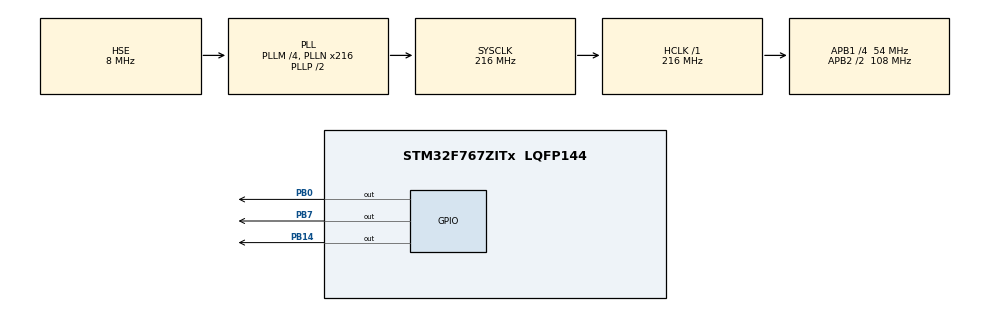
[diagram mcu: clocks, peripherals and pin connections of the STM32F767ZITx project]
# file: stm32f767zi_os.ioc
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Mcu.Family=STM32F7
Mcu.Name=STM32F767ZITx
Mcu.Package=LQFP144
NVIC.PriorityGroup=NVIC_PRIORITYGROUP_4
PA13.Mode=Trace_Asynchronous_SW
PA13.Signal=SYS_JTMS-SWDIO
PA14.Mode=Trace_Asynchronous_SW
PA14.Signal=SYS_JTCK-SWCLK
PB0.GPIO_Speed=GPIO_SPEED_FREQ_VERY_HIGH
PB0.Signal=GPIO_Output
PB14.GPIO_Speed=GPIO_SPEED_FREQ_VERY_HIGH
PB14.Signal=GPIO_Output
PB3.Mode=Trace_Asynchronous_SW
PB3.Signal=SYS_JTDO-SWO
PB7.GPIO_Speed=GPIO_SPEED_FREQ_VERY_HIGH
PB7.Signal=GPIO_Output
PH0/OSC_IN.Mode=HSE-External-Oscillator
PH0/OSC_IN.Signal=RCC_OSC_IN
PH1/OSC_OUT.Mode=HSE-External-Oscillator
PH1/OSC_OUT.Signal=RCC_OSC_OUT
ProjectManager.HeapSize=0x2000
ProjectManager.StackSize=0x4000
ProjectManager.TargetToolchain=MDK-ARM V5
RCC.AHBFreq_Value=216000000
RCC.APB1CLKDivider=RCC_HCLK_DIV4
RCC.APB1Freq_Value=54000000
RCC.APB1TimFreq_Value=108000000
RCC.APB2CLKDivider=RCC_HCLK_DIV2
RCC.APB2Freq_Value=108000000
RCC.APB2TimFreq_Value=216000000
RCC.CortexFreq_Value=216000000
RCC.HCLKFreq_Value=216000000
RCC.HSE_VALUE=8000000
RCC.HSI_VALUE=16000000
RCC.LSE_VALUE=32768
RCC.PLLM=4
RCC.PLLN=216
RCC.PLLSourceVirtual=RCC_PLLSOURCE_HSE
RCC.SYSCLKFreq_VALUE=216000000
RCC.SYSCLKSource=RCC_SYSCLKSOURCE_PLLCLK
RCC.USBFreq_Value=216000000
RCC.VCOOutputFreq_Value=432000000
board=custom

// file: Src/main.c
//SolarOS来自https://github.com/Solar914/SolarOS_STM32
//非常容易移植,移植方法是先建一个裸机工程并编译跑通,后加入SolarOS目录中的文件即可
/* USER CODE BEGIN Header */
/**
  ******************************************************************************
  * @file           : main.c
  * @brief          : Main program body
  ******************************************************************************
  * @attention
  *
  * <h2><center>&copy; Copyright (c) 2020 STMicroelectronics.
  * All rights reserved.</center></h2>
  *
  * This software component is licensed by ST under BSD 3-Clause license,
  * the "License"; You may not use this file except in compliance with the
  * License. You may obtain a copy of the License at:
  *                        opensource.org/licenses/BSD-3-Clause
  *
  ******************************************************************************
  */
/* USER CODE END Header */
//stm32f767Zi --- 2M Bytes Flash, 512K Bytes SRAM
#include "main.h"

/* USER CODE BEGIN Includes */
#include "SOLAROS.h"
#include "tBitmap.h"
#include "tlist.h"
/* USER CODE END Includes */

void SystemClock_Config(void);
static void MX_GPIO_Init(void);
/* USER CODE BEGIN PFP */
//extern u32 fac_us;
/* USER CODE END PFP */

int main(void)
{

  /* MCU Configuration--------------------------------------------------------*/

  /* Reset of all peripherals, Initializes the Flash interface and the Systick. */
  HAL_Init();

  /* Configure the system clock */
  SystemClock_Config();

  /* Initialize all configured peripherals */
  MX_GPIO_Init();

  /* Infinite loop */
  /* USER CODE BEGIN WHILE */
//  while (1)
//  {
//    /* USER CODE END WHILE */
//    /* USER CODE BEGIN 3 */
//  }

	/*初始化位图数据结构*/
	tBitmapInit(&tbitmap);

	/*任务延时队列初始化*/
	tTaskDelayedListInit();

	/*任务优先级队列初始化*/
	tTaskPrioListInit();

	/*初始化调度锁*/
	tSchedLockInit();

	/*APP初始化*/
	tInitApp();

	/*选取第一个需要运行的任务，最高优先级的任务*/
	nextTask = tTaskHighestReady();

	/*运行第一个任务*/
	tTaskRunFirst();

	/*系统成功启动之后，便不会运行到此处*/
	return 0;
	/* USER CODE END 3 */
}

void SystemClock_Config(void)
{
  RCC_OscInitTypeDef RCC_OscInitStruct = {0};
  RCC_ClkInitTypeDef RCC_ClkInitStruct = {0};

  /** Configure the main internal regulator output voltage
  */
  __HAL_RCC_PWR_CLK_ENABLE();
  __HAL_PWR_VOLTAGESCALING_CONFIG(PWR_REGULATOR_VOLTAGE_SCALE1);
  /** Initializes the CPU, AHB and APB busses clocks
  */
  RCC_OscInitStruct.OscillatorType = RCC_OSCILLATORTYPE_HSE;
  RCC_OscInitStruct.HSEState = RCC_HSE_ON;
  RCC_OscInitStruct.PLL.PLLState = RCC_PLL_ON;
  RCC_OscInitStruct.PLL.PLLSource = RCC_PLLSOURCE_HSE;
  RCC_OscInitStruct.PLL.PLLM = 4;
  RCC_OscInitStruct.PLL.PLLN = 216;
  RCC_OscInitStruct.PLL.PLLP = RCC_PLLP_DIV2;
  RCC_OscInitStruct.PLL.PLLQ = 2;
  if (HAL_RCC_OscConfig(&RCC_OscInitStruct) != HAL_OK)
  {
    Error_Handler();
  }
  /** Activate the Over-Drive mode
  */
  if (HAL_PWREx_EnableOverDrive() != HAL_OK)
  {
    Error_Handler();
  }
  /** Initializes the CPU, AHB and APB busses clocks
  */
  RCC_ClkInitStruct.ClockType = RCC_CLOCKTYPE_HCLK|RCC_CLOCKTYPE_SYSCLK
                              |RCC_CLOCKTYPE_PCLK1|RCC_CLOCKTYPE_PCLK2;
  RCC_ClkInitStruct.SYSCLKSource = RCC_SYSCLKSOURCE_PLLCLK;
  RCC_ClkInitStruct.AHBCLKDivider = RCC_SYSCLK_DIV1;
  RCC_ClkInitStruct.APB1CLKDivider = RCC_HCLK_DIV4;
  RCC_ClkInitStruct.APB2CLKDivider = RCC_HCLK_DIV2;

  if (HAL_RCC_ClockConfig(&RCC_ClkInitStruct, FLASH_LATENCY_7) != HAL_OK)
  {
    Error_Handler();
  }
}

static void MX_GPIO_Init(void)
{
  GPIO_InitTypeDef GPIO_InitStruct = {0};

  /* GPIO Ports Clock Enable */
  __HAL_RCC_GPIOH_CLK_ENABLE();
  __HAL_RCC_GPIOB_CLK_ENABLE();
  __HAL_RCC_GPIOA_CLK_ENABLE();

  /*Configure GPIO pin Output Level */
  HAL_GPIO_WritePin(GPIOB, GPIO_PIN_0|GPIO_PIN_14|GPIO_PIN_7, GPIO_PIN_RESET);

  /*Configure GPIO pins : PB0 PB14 PB7 */
  GPIO_InitStruct.Pin = GPIO_PIN_0|GPIO_PIN_14|GPIO_PIN_7;
  GPIO_InitStruct.Mode = GPIO_MODE_OUTPUT_PP;
  GPIO_InitStruct.Pull = GPIO_NOPULL;
  GPIO_InitStruct.Speed = GPIO_SPEED_FREQ_VERY_HIGH;
  HAL_GPIO_Init(GPIOB, &GPIO_InitStruct);

}

void Error_Handler(void)
{
}

/************************ (C) COPYRIGHT STMicroelectronics *****END OF FILE****/
